VERSION ""

NS_ :

BS_:

BU_: Ritz_ECU Jacinto

BO_ 625 Cruise_control_Tx: 8 Jacinto
 SG_ Cruise_control_Tx_RC : 16|8@1+ (1,0) [0|255] ""  Ritz_ECU
 SG_ Signal_CrCtl_dkPedlPos : 0|16@1- (0.0015259,0) [0|100] "%DK"  Ritz_ECU

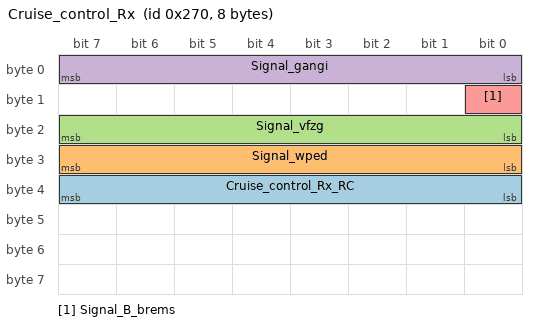
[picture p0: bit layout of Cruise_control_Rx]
BO_ 624 Cruise_control_Rx: 8 Ritz_ECU
 SG_ Cruise_control_Rx_RC : 32|8@1+ (1,0) [0|255] ""  Jacinto
 SG_ Signal_wped : 24|8@1+ (0.392157,0) [0|100] "%PED"  Jacinto
 SG_ Signal_vfzg : 16|8@1+ (1.25,0) [0|318.8] "km/h"  Jacinto
 SG_ Signal_gangi : 0|8@1+ (1,0) [0|255] "dez"  Jacinto
 SG_ Signal_B_brems : 8|1@1+ (1,0) [0|1] ""  Jacinto

BA_DEF_ BO_  "GenMsgSendType" ENUM  "Cyclic","Event","CyclicOnChange","not_used","IfActive","NoMsgSendType";
BA_DEF_ BO_  "GenMsgCycleTime" INT 0 100000;
BA_DEF_  "BusType" STRING ;
BA_DEF_DEF_  "GenMsgSendType" "NoMsgSendType";
BA_DEF_DEF_  "GenMsgCycleTime" 0;
BA_DEF_DEF_  "BusType" "CAN";
BA_ "GenMsgCycleTime" BO_ 625 10;
BA_ "GenMsgCycleTime" BO_ 624 10;

VAL_ 624 Signal_B_brems 0 "FALSE" 1 "TRUE" ;
